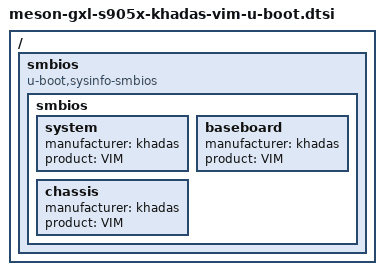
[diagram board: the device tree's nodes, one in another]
// SPDX-License-Identifier: (GPL-2.0+ OR MIT)
/*
 * Copyright (c) 2019 BayLibre, SAS.
 * Author: Neil Armstrong <narmstrong@baylibre.com>
 */

#include "meson-gxl-u-boot.dtsi"

/ {
	smbios {
		compatible = "u-boot,sysinfo-smbios";

		smbios {
			system {
				manufacturer = "khadas";
				product = "VIM";
			};

			baseboard {
				manufacturer = "khadas";
				product = "VIM";
			};

			chassis {
				manufacturer = "khadas";
				product = "VIM";
			};
		};
	};
};
